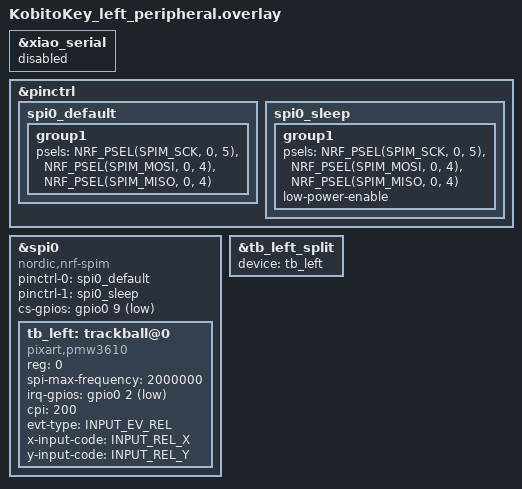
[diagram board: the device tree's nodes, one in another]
#include "kobitokey.dtsi"
#include <zephyr/dt-bindings/input/input-event-codes.h>

&xiao_serial { status = "disabled"; };

/* 左側ペリフェラルでは右トラックボールは不要 */
/delete-node/ &tb_right_split;
/delete-node/ &tb_right_listener;

&pinctrl {
    spi0_default: spi0_default {
        group1 {
            psels = <NRF_PSEL(SPIM_SCK,  0, 5)>,
                    <NRF_PSEL(SPIM_MOSI, 0, 4)>,
                    <NRF_PSEL(SPIM_MISO, 0, 4)>;
        };
    };
    spi0_sleep: spi0_sleep {
        group1 {
            psels = <NRF_PSEL(SPIM_SCK,  0, 5)>,
                    <NRF_PSEL(SPIM_MOSI, 0, 4)>,
                    <NRF_PSEL(SPIM_MISO, 0, 4)>;
            low-power-enable;
        };
    };
};

&spi0 {
    status = "okay";
    compatible = "nordic,nrf-spim";
    pinctrl-0 = <&spi0_default>;
    pinctrl-1 = <&spi0_sleep>;
    pinctrl-names = "default", "sleep";
    cs-gpios = <&gpio0 9 GPIO_ACTIVE_LOW>;

    tb_left: trackball@0 {
        status = "okay";
        compatible = "pixart,pmw3610";
        reg = <0>;
        spi-max-frequency = <2000000>;
        irq-gpios = <&gpio0 2 (GPIO_ACTIVE_LOW | GPIO_PULL_UP)>;
        cpi = <200>; /* センサー感度 */


        evt-type = <INPUT_EV_REL>;
        x-input-code = <INPUT_REL_X>;
        y-input-code = <INPUT_REL_Y>;
    };
};

/* Configure split input to send left trackball data to dongle */
&tb_left_split {
    device = <&tb_left>;
    /* ペリフェラルでは生データを送信。処理はドングル側で行う */
};
